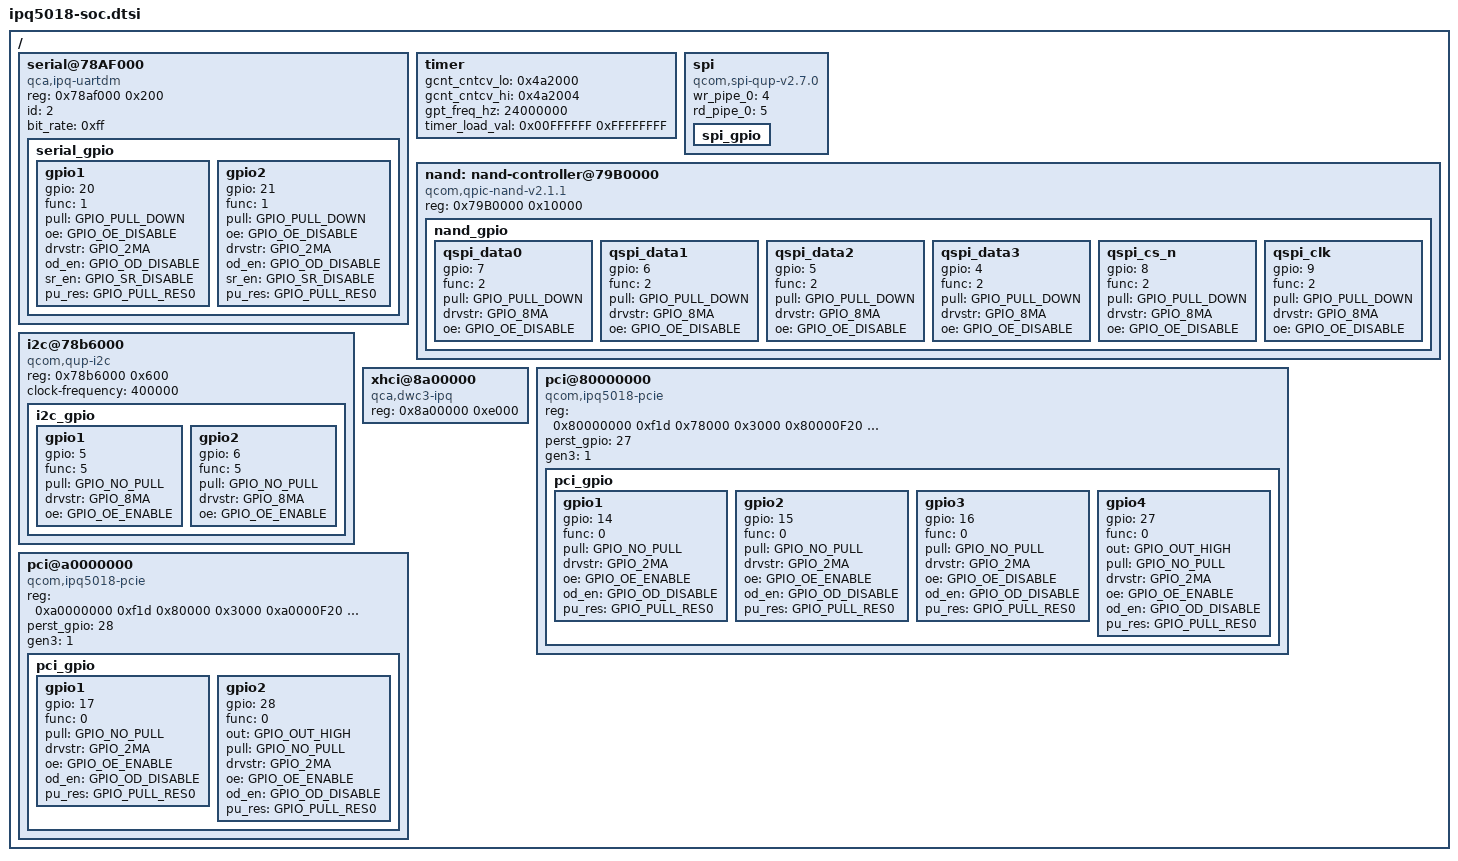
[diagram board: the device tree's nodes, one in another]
/*
 * Copyright (c) 2016-2020, The Linux Foundation. All rights reserved.
 *
 * This program is free software; you can redistribute it and/or modify
 * it under the terms of the GNU General Public License version 2 and
 * only version 2 as published by the Free Software Foundation.
 *
 * This program is distributed in the hope that it will be useful,
 * but WITHOUT ANY WARRANTY; without even the implied warranty of
 * MERCHANTABILITY or FITNESS FOR A PARTICULAR PURPOSE.  See the
 * GNU General Public License for more details.
 */

#include "skeleton.dtsi"
#include <dt-bindings/qcom/gpio-ipq5018.h>

/ {

	serial@78AF000 {
		compatible = "qca,ipq-uartdm";
		reg = <0x78af000 0x200>;
		id = <2>;
		bit_rate = <0xff>;
		status = "ok";
		serial_gpio {
			gpio1 {
				gpio = <20>;
				func = <1>;
				pull = <GPIO_PULL_DOWN>;
				oe = <GPIO_OE_DISABLE>;
				drvstr = <GPIO_2MA>;
				od_en = <GPIO_OD_DISABLE>;
				sr_en = <GPIO_SR_DISABLE>;
				pu_res =<GPIO_PULL_RES0>;
			};
			gpio2 {
				gpio = <21>;
				func = <1>;
				pull = <GPIO_PULL_DOWN>;
				oe = <GPIO_OE_DISABLE>;
				drvstr = <GPIO_2MA>;
				od_en = <GPIO_OD_DISABLE>;
				sr_en = <GPIO_SR_DISABLE>;
				pu_res =<GPIO_PULL_RES0>;
			};
		};
	};

	timer {
		gcnt_cntcv_lo = <0x4a2000>;
		gcnt_cntcv_hi = <0x4a2004>;
		gpt_freq_hz = <24000000>;
		timer_load_val = <0x00FFFFFF 0xFFFFFFFF>;
	};

	spi {
		status = "ok";
		compatible = "qcom,spi-qup-v2.7.0";
		wr_pipe_0 = <4>;
		rd_pipe_0 = <5>;
		spi_gpio {};
	};

	nand: nand-controller@79B0000 {
		#address-cells = <1>;
		#size-cells = <0>;
		compatible = "qcom,qpic-nand-v2.1.1";
		reg = <0x79B0000 0x10000>;

		nand_gpio {
			qspi_data0 {
				gpio = <7>;
				func = <2>;
				pull = <GPIO_PULL_DOWN>;
				drvstr = <GPIO_8MA>;
				oe = <GPIO_OE_DISABLE>;
			};
			qspi_data1 {
				gpio = <6>;
				func = <2>;
				pull = <GPIO_PULL_DOWN>;
				drvstr = <GPIO_8MA>;
				oe = <GPIO_OE_DISABLE>;
			};
			qspi_data2 {
				gpio = <5>;
				func = <2>;
				pull = <GPIO_PULL_DOWN>;
				drvstr = <GPIO_8MA>;
				oe = <GPIO_OE_DISABLE>;
			};
			qspi_data3 {
				gpio = <4>;
				func = <2>;
				pull = <GPIO_PULL_DOWN>;
				drvstr = <GPIO_8MA>;
				oe = <GPIO_OE_DISABLE>;
			};
			qspi_cs_n {
				gpio = <8>;
				func = <2>;
				pull = <GPIO_PULL_DOWN>;
				drvstr = <GPIO_8MA>;
				oe = <GPIO_OE_DISABLE>;
			};
			qspi_clk {
				gpio = <9>;
				func = <2>;
				pull = <GPIO_PULL_DOWN>;
				drvstr = <GPIO_8MA>;
				oe = <GPIO_OE_DISABLE>;
			};
		};
	};

	i2c@78b6000 {
		compatible = "qcom,qup-i2c";
		#address-cells = <1>;
		#size-cells = <0>;
		reg = <0x78b6000 0x600>;
		clock-frequency  = <400000>;

		i2c_gpio {
			gpio1 {
				gpio = <5>;
				func = <5>;
				pull = <GPIO_NO_PULL>;
				drvstr = <GPIO_8MA>;
				oe = <GPIO_OE_ENABLE>;
			};

			gpio2 {
				gpio = <6>;
				func = <5>;
				pull = <GPIO_NO_PULL>;
				drvstr = <GPIO_8MA>;
				oe = <GPIO_OE_ENABLE>;
			};

		};
	};

	xhci@8a00000 {
		compatible = "qca,dwc3-ipq";
		#address-cells = <1>;
		#size-cells = <1>;
		reg = <0x8a00000 0xe000>;
	};

	pci@80000000 {
		compatible = "qcom,ipq5018-pcie";
		#address-cells = <1>;
		#size-cells = <1>;
		reg = <0x80000000 0xf1d
			0x78000 0x3000
			0x80000F20 0xa8
			0x80001000 0x1000
			0x80300000 0xd00000
			0x80100000 0x100000
			0x01875004 0x40
			0x84000 0x1000>;
		reg-names = "pci_dbi", "parf", "elbi","dm_iatu", "axi_bars",
				"axi_conf", "pci_rst", "pci_phy";
		perst_gpio = <27>;
		gen3 = <1>;

		pci_gpio {
			gpio1 {
				gpio = <14>;
				func = <0>;
				pull = <GPIO_NO_PULL>;
				drvstr = <GPIO_2MA>;
				oe = <GPIO_OE_ENABLE>;
				od_en = <GPIO_OD_DISABLE>;
				pu_res = <GPIO_PULL_RES0>;
			};
			gpio2 {
				gpio = <15>;
				func = <0>;
				pull = <GPIO_NO_PULL>;
				drvstr = <GPIO_2MA>;
				oe = <GPIO_OE_ENABLE>;
				od_en = <GPIO_OD_DISABLE>;
				pu_res = <GPIO_PULL_RES0>;
			};
			gpio3 {
				gpio = <16>;
				func = <0>;
				pull = <GPIO_NO_PULL>;
				drvstr = <GPIO_2MA>;
				oe = <GPIO_OE_DISABLE>;
				od_en = <GPIO_OD_DISABLE>;
				pu_res = <GPIO_PULL_RES0>;
			};
			gpio4 {
				gpio = <27>;
				func = <0>;
				out = <GPIO_OUT_HIGH>;
				pull = <GPIO_NO_PULL>;
				drvstr = <GPIO_2MA>;
				oe = <GPIO_OE_ENABLE>;
				od_en = <GPIO_OD_DISABLE>;
				pu_res = <GPIO_PULL_RES0>;
			};
		};
	};

	pci@a0000000 {
		compatible = "qcom,ipq5018-pcie";
		#address-cells = <1>;
		#size-cells = <1>;
		reg = <0xa0000000 0xf1d
			0x80000 0x3000
			0xa0000F20 0xa8
			0xa0001000 0x1000
			0xa0300000 0xd00000
			0xa0100000 0x100000
			0x01875004 0x40
			0x84000 0x1000>;
		reg-names = "pci_dbi", "parf", "elbi","dm_iatu", "axi_bars",
				"axi_conf", "pci_rst", "pci_phy";
		perst_gpio = <28>;
		gen3 = <1>;

		pci_gpio {
			gpio1 {
				gpio = <17>;
				func = <0>;
				pull = <GPIO_NO_PULL>;
				drvstr = <GPIO_2MA>;
				oe = <GPIO_OE_ENABLE>;
				od_en = <GPIO_OD_DISABLE>;
				pu_res = <GPIO_PULL_RES0>;
			};
			gpio2 {
				gpio = <28>;
				func = <0>;
				out = <GPIO_OUT_HIGH>;
				pull = <GPIO_NO_PULL>;
				drvstr = <GPIO_2MA>;
				oe = <GPIO_OE_ENABLE>;
				od_en = <GPIO_OD_DISABLE>;
				pu_res = <GPIO_PULL_RES0>;
			};
		};
	};

};
